AUTOSAR XML (schema 4-3-0)
package /ComponentTypes
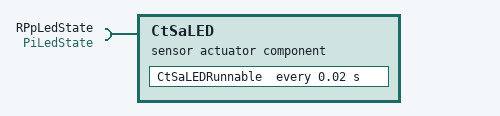
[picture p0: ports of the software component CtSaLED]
  sensor actuator sw component type CtSaLED
    require port RPpLedState: nonqueued-receiver-com-spec{data-element=DePiLedState, filter=data-filter-type=ALWAYS, init-value=0}, required-interface=PiLedState
    behavior CtSaLED_InternalBehavior: supports-multiple-instantiation=true
      timing event TMT_CtSaLEDRunnable: start-on-event=CtSaLEDRunnable, period=0.02
      runnable CtSaLEDRunnable
        data-receive-point-by-arguments:
          access REC_PiLedState_DePiLedState: accessed-variable=RPpLedState.DePiLedState
  swc implementation CtSaLED_Implementation: behavior=CtSaLED_InternalBehavior
